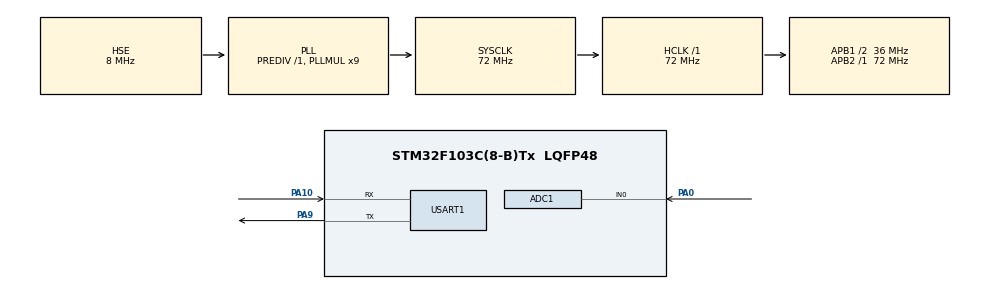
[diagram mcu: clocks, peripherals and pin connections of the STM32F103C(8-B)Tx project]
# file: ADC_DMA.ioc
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ADC1.ContinuousConvMode=ENABLE
ADC1.NbrOfConversionFlag=1
ADC1.SamplingTime-0\#ChannelRegularConversion=ADC_SAMPLETIME_55CYCLES_5
ADC1.master=1
Dma.ADC1.0.Direction=DMA_PERIPH_TO_MEMORY
Dma.ADC1.0.Instance=DMA1_Channel1
Dma.ADC1.0.MemDataAlignment=DMA_MDATAALIGN_HALFWORD
Dma.ADC1.0.MemInc=DMA_MINC_ENABLE
Dma.ADC1.0.Mode=DMA_CIRCULAR
Dma.ADC1.0.PeriphDataAlignment=DMA_PDATAALIGN_HALFWORD
Dma.ADC1.0.PeriphInc=DMA_PINC_DISABLE
Dma.ADC1.0.Priority=DMA_PRIORITY_LOW
Dma.Request0=ADC1
Mcu.Family=STM32F1
Mcu.Name=STM32F103C(8-B)Tx
Mcu.Package=LQFP48
NVIC.DMA1_Channel1_IRQn=true\:0\:0\:false\:false\:true\:false\:true\:true
NVIC.PriorityGroup=NVIC_PRIORITYGROUP_4
PA0-WKUP.Signal=ADCx_IN0
PA10.Mode=Asynchronous
PA10.Signal=USART1_RX
PA13.Mode=Serial_Wire
PA13.Signal=SYS_JTMS-SWDIO
PA14.Mode=Serial_Wire
PA14.Signal=SYS_JTCK-SWCLK
PA9.Mode=Asynchronous
PA9.Signal=USART1_TX
PD0-OSC_IN.Mode=HSE-External-Oscillator
PD0-OSC_IN.Signal=RCC_OSC_IN
PD1-OSC_OUT.Mode=HSE-External-Oscillator
PD1-OSC_OUT.Signal=RCC_OSC_OUT
ProjectManager.HeapSize=0x200
ProjectManager.StackSize=0x400
ProjectManager.TargetToolchain=STM32CubeIDE
RCC.ADCPresc=RCC_ADCPCLK2_DIV6
RCC.AHBFreq_Value=72000000
RCC.APB1CLKDivider=RCC_HCLK_DIV2
RCC.APB1Freq_Value=36000000
RCC.APB1TimFreq_Value=72000000
RCC.APB2Freq_Value=72000000
RCC.APB2TimFreq_Value=72000000
RCC.HCLKFreq_Value=72000000
RCC.PLLMUL=RCC_PLL_MUL9
RCC.PLLSourceVirtual=RCC_PLLSOURCE_HSE
RCC.SYSCLKFreq_VALUE=72000000
RCC.SYSCLKSource=RCC_SYSCLKSOURCE_PLLCLK
RCC.USBFreq_Value=72000000
SH.ADCx_IN0.0=ADC1_IN0,IN0
USART1.VirtualMode=VM_ASYNC
board=custom

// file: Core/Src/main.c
/* USER CODE BEGIN Header */
/**
  ******************************************************************************
  * @file           : main.c
  * @brief          : Main program body
  ******************************************************************************
  * @attention
  *
  * Copyright (c) 2025 STMicroelectronics.
  * All rights reserved.
  *
  * This software is licensed under terms that can be found in the LICENSE file
  * in the root directory of this software component.
  * If no LICENSE file comes with this software, it is provided AS-IS.
  *
  ******************************************************************************
  */
/* USER CODE END Header */
#include "main.h"

/* USER CODE BEGIN Includes */
#include "stdio.h"
#include "string.h"
/* USER CODE END Includes */

/* USER CODE BEGIN PD */
#define UART_TIMEOUT       100   // Timeout en ms para transmisión UART
#define BUFFER_SIZE        20    // Tamaño del buffer de transmisión
#define ADC_BUFFER_SIZE    1     // Número de conversiones ADC a almacenar
#define VREF               3.3f  // Voltaje de referencia del ADC (V)
#define ADC_RESOLUTION     4095  // Resolución ADC de 12 bits (2^12 - 1)
#define DISPLAY_DELAY      100   // Delay entre transmisiones UART (ms)
/* USER CODE END PD */

ADC_HandleTypeDef hadc1;
DMA_HandleTypeDef hdma_adc1;

UART_HandleTypeDef huart1;

/* USER CODE BEGIN PV */

/**
 * @brief Buffer para almacenar valores convertidos por el ADC
 * @note  - Tipo uint16_t porque el ADC de 12 bits cabe en 16 bits
 *        - Array de tamaño 1 para un solo canal
 *        - El DMA escribe directamente en esta ubicación
 *        - En modo circular, se actualiza continuamente
 *
 * IMPORTANTE: Se usa uint16_t en lugar de uint32_t porque:
 * - El ADC del STM32F103 es de 12 bits (0-4095)
 * - uint16_t optimiza el uso de memoria
 * - La función HAL_ADC_Start_DMA acepta uint32_t* pero el cast es seguro
 */
uint16_t ADC_VAL[ADC_BUFFER_SIZE];

/**
 * @brief Buffer para formatear la cadena a transmitir por UART
 * @note  Almacena el mensaje "ADC: XXXX (X.XXV)\r\n"
 */
char buffer[BUFFER_SIZE];

/**
 * @brief Bandera volátil que indica cuando hay datos ADC listos
 * @note  - volatile: Indica al compilador que esta variable puede cambiar
 *          inesperadamente (desde una ISR), evitando optimizaciones incorrectas
 *        - Se establece en 1 en el callback del DMA
 *        - Se limpia en 0 en el bucle principal después de procesar
 *
 * PATRÓN DE USO:
 * - ISR: adc_ready = 1 (señaliza datos listos)
 * - Main: if(adc_ready) { procesar(); adc_ready = 0; }
 */
volatile uint8_t adc_ready = 0;
/* USER CODE END PV */

void SystemClock_Config(void);
static void MX_GPIO_Init(void);
static void MX_DMA_Init(void);
static void MX_ADC1_Init(void);
static void MX_USART1_UART_Init(void);

int main(void)
{

  /* MCU Configuration--------------------------------------------------------*/

  /* Reset of all peripherals, Initializes the Flash interface and the Systick. */
  HAL_Init();

  /* Configure the system clock */
  SystemClock_Config();

  /* Initialize all configured peripherals */
  MX_GPIO_Init();
  MX_DMA_Init();
  MX_ADC1_Init();
  MX_USART1_UART_Init();
  /* USER CODE BEGIN 2 */

  /**
   * ========== INICIALIZACIÓN DEL ADC EN MODO DMA ==========
   *
   * HAL_ADC_Start_DMA():
   * - Inicia el ADC en modo DMA con conversión continua
   * - Configura el DMA para transferir datos automáticamente
   * - El DMA opera en modo circular (reinicio automático)
   *
   * PARÁMETROS:
   * @param &hadc1: Puntero al manejador del ADC
   * @param (uint32_t *)ADC_VAL: Dirección de memoria destino
   *        - Se hace cast a uint32_t* aunque ADC_VAL es uint16_t[]
   *        - Esto es seguro porque la HAL maneja correctamente el tamaño
   * @param 1: Número de conversiones a transferir antes de generar interrupción
   *
   */
  HAL_ADC_Start_DMA(&hadc1, (uint32_t *)ADC_VAL, ADC_BUFFER_SIZE);
  /* USER CODE END 2 */

  /* Infinite loop */
  /* USER CODE BEGIN WHILE */
  while (1)
  {
	  /*
	   * ========== PROCESAMIENTO DE DATOS ADC ==========
	   *
	   * Este bucle espera la bandera adc_ready que es establecida
	   * por el callback del DMA cuando se completa una transferencia.
	   */
	  if(adc_ready == 1)
	  {
		  /* ========== PASO 1: Limpiar la bandera ========== */
		  /**
		    * Limpiamos la bandera inmediatamente para:
			* - Evitar procesar el mismo dato múltiples veces
			* - Sincronizar correctamente el flujo de datos
			*/
		  adc_ready = 0;

		  /* ========== PASO 2: Calcular el voltaje ========== */
		  /**
		   * Conversión de valor digital a voltaje analógico:
		   *
		   * Fórmula: Voltaje = (Valor_ADC / Resolución_Máxima) × VREF
		   *
		   * Donde:
		   * - ADC_VAL[0]: Valor digital del ADC (0-4095)
		   * - ADC_RESOLUTION: 4095 (2^12 - 1 para 12 bits)
		   * - VREF: Voltaje de referencia (típicamente 3.3V)
		   *
		   * Ejemplo:
		   * - Si ADC_VAL[0] = 2048 (mitad de escala)
		   * - voltage = (2048 / 4095) × 3.3V = 1.65V
		   *
		   * NOTA: Se usa 3.3f con 'f' para forzar aritmética de punto flotante
		   */
		  float voltage = (ADC_VAL[0] * VREF) / ADC_RESOLUTION;

		  /* ========== PASO 3: Formatear y transmitir ========== */
		  sprintf(buffer, "ADC: %u (%.2fV)\r\n", ADC_VAL[0], voltage);

		  HAL_UART_Transmit(&huart1, (uint8_t*)buffer, strlen(buffer), 100);
	  }

	  /* ========== PASO 4: Pequeño delay para control de flujo ========== */
	  HAL_Delay(DISPLAY_DELAY);

    /* USER CODE END WHILE */

  }
}

void SystemClock_Config(void)
{
  RCC_OscInitTypeDef RCC_OscInitStruct = {0};
  RCC_ClkInitTypeDef RCC_ClkInitStruct = {0};
  RCC_PeriphCLKInitTypeDef PeriphClkInit = {0};

  /** Initializes the RCC Oscillators according to the specified parameters
  * in the RCC_OscInitTypeDef structure.
  */
  RCC_OscInitStruct.OscillatorType = RCC_OSCILLATORTYPE_HSE;
  RCC_OscInitStruct.HSEState = RCC_HSE_ON;
  RCC_OscInitStruct.HSEPredivValue = RCC_HSE_PREDIV_DIV1;
  RCC_OscInitStruct.HSIState = RCC_HSI_ON;
  RCC_OscInitStruct.PLL.PLLState = RCC_PLL_ON;
  RCC_OscInitStruct.PLL.PLLSource = RCC_PLLSOURCE_HSE;
  RCC_OscInitStruct.PLL.PLLMUL = RCC_PLL_MUL9;
  if (HAL_RCC_OscConfig(&RCC_OscInitStruct) != HAL_OK)
  {
    Error_Handler();
  }

  /** Initializes the CPU, AHB and APB buses clocks
  */
  RCC_ClkInitStruct.ClockType = RCC_CLOCKTYPE_HCLK|RCC_CLOCKTYPE_SYSCLK
                              |RCC_CLOCKTYPE_PCLK1|RCC_CLOCKTYPE_PCLK2;
  RCC_ClkInitStruct.SYSCLKSource = RCC_SYSCLKSOURCE_PLLCLK;
  RCC_ClkInitStruct.AHBCLKDivider = RCC_SYSCLK_DIV1;
  RCC_ClkInitStruct.APB1CLKDivider = RCC_HCLK_DIV2;
  RCC_ClkInitStruct.APB2CLKDivider = RCC_HCLK_DIV1;

  if (HAL_RCC_ClockConfig(&RCC_ClkInitStruct, FLASH_LATENCY_2) != HAL_OK)
  {
    Error_Handler();
  }
  PeriphClkInit.PeriphClockSelection = RCC_PERIPHCLK_ADC;
  PeriphClkInit.AdcClockSelection = RCC_ADCPCLK2_DIV6;
  if (HAL_RCCEx_PeriphCLKConfig(&PeriphClkInit) != HAL_OK)
  {
    Error_Handler();
  }
}

static void MX_ADC1_Init(void)
{

  ADC_ChannelConfTypeDef sConfig = {0};

  /** Common config
  */
  hadc1.Instance = ADC1;
  hadc1.Init.ScanConvMode = ADC_SCAN_DISABLE;
  hadc1.Init.ContinuousConvMode = ENABLE;
  hadc1.Init.DiscontinuousConvMode = DISABLE;
  hadc1.Init.ExternalTrigConv = ADC_SOFTWARE_START;
  hadc1.Init.DataAlign = ADC_DATAALIGN_RIGHT;
  hadc1.Init.NbrOfConversion = 1;
  if (HAL_ADC_Init(&hadc1) != HAL_OK)
  {
    Error_Handler();
  }

  /** Configure Regular Channel
  */
  sConfig.Channel = ADC_CHANNEL_0;
  sConfig.Rank = ADC_REGULAR_RANK_1;
  sConfig.SamplingTime = ADC_SAMPLETIME_55CYCLES_5;
  if (HAL_ADC_ConfigChannel(&hadc1, &sConfig) != HAL_OK)
  {
    Error_Handler();
  }

}

static void MX_USART1_UART_Init(void)
{

  huart1.Instance = USART1;
  huart1.Init.BaudRate = 115200;
  huart1.Init.WordLength = UART_WORDLENGTH_8B;
  huart1.Init.StopBits = UART_STOPBITS_1;
  huart1.Init.Parity = UART_PARITY_NONE;
  huart1.Init.Mode = UART_MODE_TX_RX;
  huart1.Init.HwFlowCtl = UART_HWCONTROL_NONE;
  huart1.Init.OverSampling = UART_OVERSAMPLING_16;
  if (HAL_UART_Init(&huart1) != HAL_OK)
  {
    Error_Handler();
  }

}

static void MX_DMA_Init(void)
{

  /* DMA controller clock enable */
  __HAL_RCC_DMA1_CLK_ENABLE();

  /* DMA interrupt init */
  /* DMA1_Channel1_IRQn interrupt configuration */
  HAL_NVIC_SetPriority(DMA1_Channel1_IRQn, 0, 0);
  HAL_NVIC_EnableIRQ(DMA1_Channel1_IRQn);

}

static void MX_GPIO_Init(void)
{

  /* GPIO Ports Clock Enable */
  __HAL_RCC_GPIOD_CLK_ENABLE();
  __HAL_RCC_GPIOA_CLK_ENABLE();

}

/* USER CODE BEGIN 4 */

/**
  * @brief  Callback ejecutado cuando el DMA completa la conversión de todos los canales.
  * @param  hadc: puntero al manejador del ADC.
  * @retval None
  */
void HAL_ADC_ConvCpltCallback(ADC_HandleTypeDef *hadc)
{
	/**
	 * Verificación de instancia:
	 * - Buena práctica para sistemas con múltiples ADCs
	 * - Evita conflictos si se usan ADC1, ADC2, ADC3 simultáneamente
	 * - En este proyecto simple podría omitirse, pero es buena práctica
	 */
	if(hadc->Instance == ADC1)
	{
		adc_ready = 1;
	}
}
/* USER CODE END 4 */

void Error_Handler(void)
{
  __disable_irq();
  while (1)
  {
  }
}
